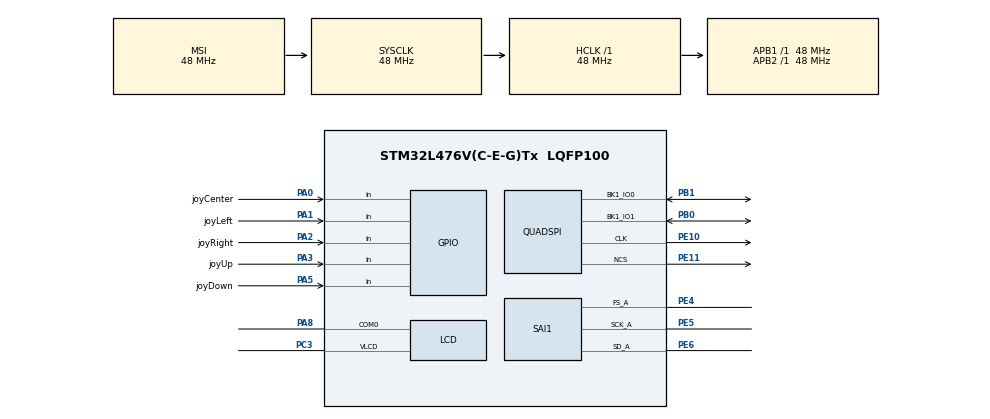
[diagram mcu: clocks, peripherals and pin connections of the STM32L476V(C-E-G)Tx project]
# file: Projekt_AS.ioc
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Mcu.Family=STM32L4
Mcu.Name=STM32L476V(C-E-G)Tx
Mcu.Package=LQFP100
NVIC.PriorityGroup=NVIC_PRIORITYGROUP_4
PA0.GPIO_Label=joyCenter
PA0.Signal=GPIO_Input
PA1.GPIO_Label=joyLeft
PA1.Signal=GPIO_Input
PA2.GPIO_Label=joyRight
PA2.Signal=GPIO_Input
PA3.GPIO_Label=joyUp
PA3.GPIO_PuPd=GPIO_PULLDOWN
PA3.Signal=GPIO_Input
PA5.GPIO_Label=joyDown
PA5.Signal=GPIO_Input
PA8.Mode=Static
PA8.Signal=LCD_COM0
PB0.Mode=Single Bank 2IOs
PB0.Signal=QUADSPI_BK1_IO1
PB1.Mode=Single Bank 2IOs
PB1.Signal=QUADSPI_BK1_IO0
PC14-OSC32_IN\ (PC14).Mode=LSE-External-Oscillator
PC14-OSC32_IN\ (PC14).Signal=RCC_OSC32_IN
PC15-OSC32_OUT\ (PC15).Mode=LSE-External-Oscillator
PC15-OSC32_OUT\ (PC15).Signal=RCC_OSC32_OUT
PC3.Mode=Static
PC3.Signal=LCD_VLCD
PE10.Mode=Single Bank 2IOs
PE10.Signal=QUADSPI_CLK
PE11.Mode=Single Bank 2IOs
PE11.Signal=QUADSPI_NCS
PE4.Mode=SAI_A_Master
PE4.Signal=SAI1_FS_A
PE5.Mode=SAI_A_Master
PE5.Signal=SAI1_SCK_A
PE6.Mode=SAI_A_Master
PE6.Signal=SAI1_SD_A
PH0-OSC_IN\ (PH0).Mode=HSE-External-Oscillator
PH0-OSC_IN\ (PH0).Signal=RCC_OSC_IN
PH1-OSC_OUT\ (PH1).Mode=HSE-External-Oscillator
PH1-OSC_OUT\ (PH1).Signal=RCC_OSC_OUT
ProjectManager.HeapSize=0x200
ProjectManager.StackSize=0x400
ProjectManager.TargetToolchain=TrueSTUDIO
RCC.ADCFreq_Value=128000000
RCC.AHBFreq_Value=48000000
RCC.APB1Freq_Value=48000000
RCC.APB1TimFreq_Value=48000000
RCC.APB2Freq_Value=48000000
RCC.APB2TimFreq_Value=48000000
RCC.CortexFreq_Value=48000000
RCC.HCLKFreq_Value=48000000
RCC.HSE_VALUE=8000000
RCC.HSI_VALUE=16000000
RCC.MSIClockRange=RCC_MSIRANGE_11
RCC.MSI_VALUE=48000000
RCC.PLLM=3
RCC.PLLSAI1N=16
RCC.PLLSAI1P=RCC_PLLP_DIV17
RCC.SYSCLKFreq_VALUE=48000000
RCC.USBFreq_Value=128000000
RCC.VCOOutputFreq_Value=128000000
SAI1.Instance-SAI_A_Master=SAI$Index_Block_A
SAI1.MClockEnable-SAI_A_Master=SAI_MASTERCLOCK_DISABLE
SAI1.Synchro-SAI_A_Master=SAI_ASYNCHRONOUS
SAI1.VirtualMode-SAI_A_Master=VM_MASTER
VP_DFSDM1_VS_IN0.Mode=Parallel_Input_ch0
board=Projekt_AS

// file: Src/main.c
/**
  ******************************************************************************
  * @file           : main.c
  * @brief          : Main program body
  ******************************************************************************
  ** This notice applies to any and all portions of this file
  * that are not between comment pairs USER CODE BEGIN and
  * USER CODE END. Other portions of this file, whether
  * inserted by the user or by software development tools
  * are owned by their respective copyright owners.
  *
  * COPYRIGHT(c) 2018 STMicroelectronics
  *
  * Redistribution and use in source and binary forms, with or without modification,
  * are permitted provided that the following conditions are met:
  *   1. Redistributions of source code must retain the above copyright notice,
  *      this list of conditions and the following disclaimer.
  *   2. Redistributions in binary form must reproduce the above copyright notice,
  *      this list of conditions and the following disclaimer in the documentation
  *      and/or other materials provided with the distribution.
  *   3. Neither the name of STMicroelectronics nor the names of its contributors
  *      may be used to endorse or promote products derived from this software
  *      without specific prior written permission.
  *
  * THIS SOFTWARE IS PROVIDED BY THE COPYRIGHT HOLDERS AND CONTRIBUTORS "AS IS"
  * AND ANY EXPRESS OR IMPLIED WARRANTIES, INCLUDING, BUT NOT LIMITED TO, THE
  * IMPLIED WARRANTIES OF MERCHANTABILITY AND FITNESS FOR A PARTICULAR PURPOSE ARE
  * DISCLAIMED. IN NO EVENT SHALL THE COPYRIGHT HOLDER OR CONTRIBUTORS BE LIABLE
  * FOR ANY DIRECT, INDIRECT, INCIDENTAL, SPECIAL, EXEMPLARY, OR CONSEQUENTIAL
  * DAMAGES (INCLUDING, BUT NOT LIMITED TO, PROCUREMENT OF SUBSTITUTE GOODS OR
  * SERVICES; LOSS OF USE, DATA, OR PROFITS; OR BUSINESS INTERRUPTION) HOWEVER
  * CAUSED AND ON ANY THEORY OF LIABILITY, WHETHER IN CONTRACT, STRICT LIABILITY,
  * OR TORT (INCLUDING NEGLIGENCE OR OTHERWISE) ARISING IN ANY WAY OUT OF THE USE
  * OF THIS SOFTWARE, EVEN IF ADVISED OF THE POSSIBILITY OF SUCH DAMAGE.
  *
  ******************************************************************************
  */
#include "main.h"
#include "stm32l4xx_hal.h"
#include "dfsdm.h"
#include "lcd.h"
#include "quadspi.h"
#include "sai.h"
#include "gpio.h"

/* USER CODE BEGIN Includes */
#include "joystick.h"

/* USER CODE END Includes */

/* USER CODE BEGIN PV */
/* Private variables ---------------------------------------------------------*/

/* USER CODE END PV */

void SystemClock_Config(void);

/* USER CODE BEGIN PFP */
/* Private function prototypes -----------------------------------------------*/

/* USER CODE END PFP */

int main(void)
{

  /* MCU Configuration----------------------------------------------------------*/

  /* Reset of all peripherals, Initializes the Flash interface and the Systick. */
  HAL_Init();

  /* Configure the system clock */
  SystemClock_Config();

  /* Initialize all configured peripherals */
  MX_GPIO_Init();
  MX_SAI1_Init();
  MX_DFSDM1_Init();
 // MX_LCD_Init();
  MX_QUADSPI_Init();
  /* USER CODE BEGIN 2 */
  BSP_LCD_GLASS_Init();
  BSP_LCD_GLASS_DisplayString("elo");
  /* USER CODE END 2 */

  /* Infinite loop */
  /* USER CODE BEGIN WHILE */
  while (1)
  {
	  if(isJoyClicked(joyCenter_Pin,joyCenter_GPIO_Port))
		  doJoyAction(joyCenter_Pin,mainMenu);
	  if(isJoyClicked(joyUp_Pin,joyUp_GPIO_Port))
	  		  doJoyAction(joyUp_Pin,mainMenu);
	  HAL_Delay(200);

  /* USER CODE END WHILE */

  }

}

void SystemClock_Config(void)
{

  RCC_OscInitTypeDef RCC_OscInitStruct;
  RCC_ClkInitTypeDef RCC_ClkInitStruct;
  RCC_PeriphCLKInitTypeDef PeriphClkInit;

    /**Configure LSE Drive Capability
    */
  HAL_PWR_EnableBkUpAccess();

  __HAL_RCC_LSEDRIVE_CONFIG(RCC_LSEDRIVE_LOW);

    /**Initializes the CPU, AHB and APB busses clocks
    */
  RCC_OscInitStruct.OscillatorType = RCC_OSCILLATORTYPE_LSI|RCC_OSCILLATORTYPE_LSE
                              |RCC_OSCILLATORTYPE_MSI;
  RCC_OscInitStruct.LSEState = RCC_LSE_ON;
  RCC_OscInitStruct.LSIState = RCC_LSI_ON;
  RCC_OscInitStruct.MSIState = RCC_MSI_ON;
  RCC_OscInitStruct.MSICalibrationValue = 0;
  RCC_OscInitStruct.MSIClockRange = RCC_MSIRANGE_11;
  RCC_OscInitStruct.PLL.PLLState = RCC_PLL_NONE;
  if (HAL_RCC_OscConfig(&RCC_OscInitStruct) != HAL_OK)
  {
    _Error_Handler(__FILE__, __LINE__);
  }

    /**Initializes the CPU, AHB and APB busses clocks
    */
  RCC_ClkInitStruct.ClockType = RCC_CLOCKTYPE_HCLK|RCC_CLOCKTYPE_SYSCLK
                              |RCC_CLOCKTYPE_PCLK1|RCC_CLOCKTYPE_PCLK2;
  RCC_ClkInitStruct.SYSCLKSource = RCC_SYSCLKSOURCE_MSI;
  RCC_ClkInitStruct.AHBCLKDivider = RCC_SYSCLK_DIV1;
  RCC_ClkInitStruct.APB1CLKDivider = RCC_HCLK_DIV1;
  RCC_ClkInitStruct.APB2CLKDivider = RCC_HCLK_DIV1;

  if (HAL_RCC_ClockConfig(&RCC_ClkInitStruct, FLASH_LATENCY_2) != HAL_OK)
  {
    _Error_Handler(__FILE__, __LINE__);
  }

  PeriphClkInit.PeriphClockSelection = RCC_PERIPHCLK_RTC|RCC_PERIPHCLK_SAI1
                              |RCC_PERIPHCLK_DFSDM1;
  PeriphClkInit.Sai1ClockSelection = RCC_SAI1CLKSOURCE_PLLSAI1;
  PeriphClkInit.Dfsdm1ClockSelection = RCC_DFSDM1CLKSOURCE_PCLK;
  PeriphClkInit.RTCClockSelection = RCC_RTCCLKSOURCE_LSI;
  PeriphClkInit.PLLSAI1.PLLSAI1Source = RCC_PLLSOURCE_MSI;
  PeriphClkInit.PLLSAI1.PLLSAI1M = 3;
  PeriphClkInit.PLLSAI1.PLLSAI1N = 16;
  PeriphClkInit.PLLSAI1.PLLSAI1P = RCC_PLLP_DIV17;
  PeriphClkInit.PLLSAI1.PLLSAI1Q = RCC_PLLQ_DIV2;
  PeriphClkInit.PLLSAI1.PLLSAI1R = RCC_PLLR_DIV2;
  PeriphClkInit.PLLSAI1.PLLSAI1ClockOut = RCC_PLLSAI1_SAI1CLK;
  if (HAL_RCCEx_PeriphCLKConfig(&PeriphClkInit) != HAL_OK)
  {
    _Error_Handler(__FILE__, __LINE__);
  }

    /**Configure the main internal regulator output voltage
    */
  if (HAL_PWREx_ControlVoltageScaling(PWR_REGULATOR_VOLTAGE_SCALE1) != HAL_OK)
  {
    _Error_Handler(__FILE__, __LINE__);
  }

    /**Configure the Systick interrupt time
    */
  HAL_SYSTICK_Config(HAL_RCC_GetHCLKFreq()/1000);

    /**Configure the Systick
    */
  HAL_SYSTICK_CLKSourceConfig(SYSTICK_CLKSOURCE_HCLK);

    /**Enable MSI Auto calibration
    */
  HAL_RCCEx_EnableMSIPLLMode();

  /* SysTick_IRQn interrupt configuration */
  HAL_NVIC_SetPriority(SysTick_IRQn, 0, 0);
}

void _Error_Handler(char *file, int line)
{
  while(1)
  {
  }
}

/************************ (C) COPYRIGHT STMicroelectronics *****END OF FILE****/
